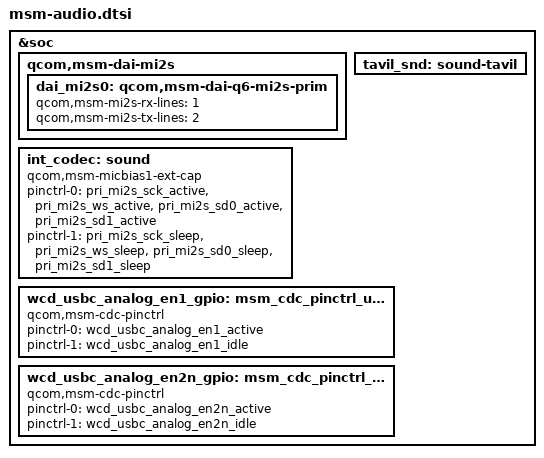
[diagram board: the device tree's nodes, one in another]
/*
 * Copyright (c) 2015-2017, The Linux Foundation. All rights reserved.
 * Copyright (C) 2018 XiaoMi, Inc.
 *
 * This program is free software; you can redistribute it and/or modify
 * it under the terms of the GNU General Public License version 2 and
 * only version 2 as published by the Free Software Foundation.
 *
 * This program is distributed in the hope that it will be useful,
 * but WITHOUT ANY WARRANTY; without even the implied warranty of
 * MERCHANTABILITY or FITNESS FOR A PARTICULAR PURPOSE.  See the
 * GNU General Public License for more details.
 */

&soc {
	qcom,msm-dai-mi2s {
		dai_mi2s0: qcom,msm-dai-q6-mi2s-prim {
			qcom,msm-mi2s-rx-lines = <1>;
			qcom,msm-mi2s-tx-lines = <2>;
		};
	};
	tavil_snd: sound-tavil {
		/delete-property/qcom,usbc-analog-en1_gpio;
		/delete-property/qcom,usbc-analog-en2_n_gpio;
	};
	int_codec: sound {
		qcom,msm-micbias1-ext-cap;
		/delete-property/qcom,msm-micbias2-ext-cap;
		/delete-property/qcom,us-euro-gpios;
		pinctrl-names = "pri_i2s_active", "pri_i2s_sleep";
		pinctrl-0 = <&pri_mi2s_sck_active &pri_mi2s_ws_active
				&pri_mi2s_sd0_active &pri_mi2s_sd1_active>;
		pinctrl-1 = <&pri_mi2s_sck_sleep &pri_mi2s_ws_sleep
				&pri_mi2s_sd0_sleep &pri_mi2s_sd1_sleep>;
	};
	wcd_usbc_analog_en1_gpio: msm_cdc_pinctrl_usbc_audio_en1 {
		compatible = "qcom,msm-cdc-pinctrl";
		pinctrl-names = "aud_active", "aud_sleep";
		pinctrl-0 = <&wcd_usbc_analog_en1_active>;
		pinctrl-1 = <&wcd_usbc_analog_en1_idle>;
	};

	wcd_usbc_analog_en2n_gpio: msm_cdc_pinctrl_usbc_audio_en2 {
		compatible = "qcom,msm-cdc-pinctrl";
		pinctrl-names = "aud_active", "aud_sleep";
		pinctrl-0 = <&wcd_usbc_analog_en2n_active>;
		pinctrl-1 = <&wcd_usbc_analog_en2n_idle>;
	};
};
